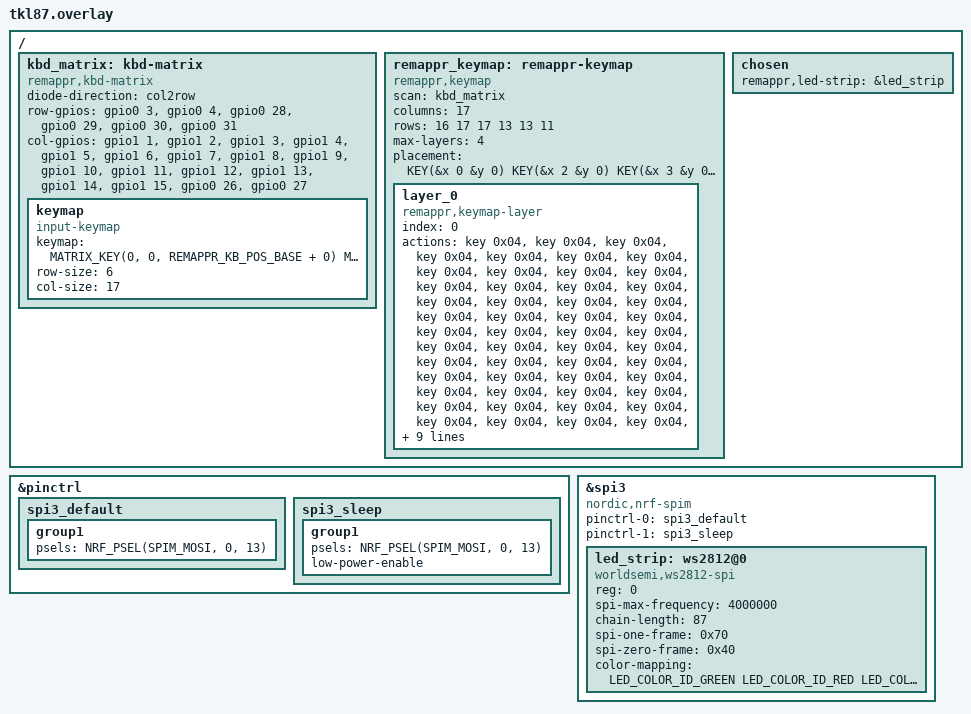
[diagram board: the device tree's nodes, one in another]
/*
 * TKL 87 — Remappr shield (generated by remappr).
 *
 * Drop this directory into a remappr-firmware checkout under
 * boards/shields/tkl87/ and build with -DSHIELD=tkl87. Verify the
 * row/col GPIO specs against your wiring — remappr derives the matrix
 * cells from physical key position, not the electrical matrix.
 *
 * SPDX-License-Identifier: Apache-2.0
 */

#include <zephyr/dt-bindings/input/input-event-codes.h>
#include <zephyr/dt-bindings/input/keymap.h>
#include <dt-bindings/remappr/keys.h>
#include <dt-bindings/remappr/layout.h>
#include <remappr/keymap-tokens.dtsi>
#include <remappr/behavior-tokens.dtsi>
#include <zephyr/dt-bindings/led/led.h>

/ {
	kbd_matrix: kbd-matrix {
		compatible = "remappr,kbd-matrix";
		diode-direction = "col2row";
		row-gpios =
			<&gpio0 3 (GPIO_ACTIVE_HIGH | GPIO_PULL_DOWN)>,
			<&gpio0 4 (GPIO_ACTIVE_HIGH | GPIO_PULL_DOWN)>,
			<&gpio0 28 (GPIO_ACTIVE_HIGH | GPIO_PULL_DOWN)>,
			<&gpio0 29 (GPIO_ACTIVE_HIGH | GPIO_PULL_DOWN)>,
			<&gpio0 30 (GPIO_ACTIVE_HIGH | GPIO_PULL_DOWN)>,
			<&gpio0 31 (GPIO_ACTIVE_HIGH | GPIO_PULL_DOWN)>;
		col-gpios =
			<&gpio1 1 GPIO_ACTIVE_HIGH>,
			<&gpio1 2 GPIO_ACTIVE_HIGH>,
			<&gpio1 3 GPIO_ACTIVE_HIGH>,
			<&gpio1 4 GPIO_ACTIVE_HIGH>,
			<&gpio1 5 GPIO_ACTIVE_HIGH>,
			<&gpio1 6 GPIO_ACTIVE_HIGH>,
			<&gpio1 7 GPIO_ACTIVE_HIGH>,
			<&gpio1 8 GPIO_ACTIVE_HIGH>,
			<&gpio1 9 GPIO_ACTIVE_HIGH>,
			<&gpio1 10 GPIO_ACTIVE_HIGH>,
			<&gpio1 11 GPIO_ACTIVE_HIGH>,
			<&gpio1 12 GPIO_ACTIVE_HIGH>,
			<&gpio1 13 GPIO_ACTIVE_HIGH>,
			<&gpio1 14 GPIO_ACTIVE_HIGH>,
			<&gpio1 15 GPIO_ACTIVE_HIGH>,
			<&gpio0 26 GPIO_ACTIVE_HIGH>,
			<&gpio0 27 GPIO_ACTIVE_HIGH>;

		keymap {
			compatible = "input-keymap";
			keymap = <
				MATRIX_KEY(0, 0, REMAPPR_KB_POS_BASE + 0) MATRIX_KEY(0, 1, REMAPPR_KB_POS_BASE + 1) MATRIX_KEY(0, 2, REMAPPR_KB_POS_BASE + 2) MATRIX_KEY(0, 3, REMAPPR_KB_POS_BASE + 3) MATRIX_KEY(0, 4, REMAPPR_KB_POS_BASE + 4) MATRIX_KEY(0, 5, REMAPPR_KB_POS_BASE + 5) MATRIX_KEY(0, 6, REMAPPR_KB_POS_BASE + 6) MATRIX_KEY(0, 7, REMAPPR_KB_POS_BASE + 7) MATRIX_KEY(0, 8, REMAPPR_KB_POS_BASE + 8) MATRIX_KEY(0, 9, REMAPPR_KB_POS_BASE + 9) MATRIX_KEY(0, 10, REMAPPR_KB_POS_BASE + 10) MATRIX_KEY(0, 11, REMAPPR_KB_POS_BASE + 11) MATRIX_KEY(0, 12, REMAPPR_KB_POS_BASE + 12) MATRIX_KEY(0, 13, REMAPPR_KB_POS_BASE + 13) MATRIX_KEY(0, 14, REMAPPR_KB_POS_BASE + 14) MATRIX_KEY(0, 15, REMAPPR_KB_POS_BASE + 15)
				MATRIX_KEY(1, 0, REMAPPR_KB_POS_BASE + 16) MATRIX_KEY(1, 1, REMAPPR_KB_POS_BASE + 17) MATRIX_KEY(1, 2, REMAPPR_KB_POS_BASE + 18) MATRIX_KEY(1, 3, REMAPPR_KB_POS_BASE + 19) MATRIX_KEY(1, 4, REMAPPR_KB_POS_BASE + 20) MATRIX_KEY(1, 5, REMAPPR_KB_POS_BASE + 21) MATRIX_KEY(1, 6, REMAPPR_KB_POS_BASE + 22) MATRIX_KEY(1, 7, REMAPPR_KB_POS_BASE + 23) MATRIX_KEY(1, 8, REMAPPR_KB_POS_BASE + 24) MATRIX_KEY(1, 9, REMAPPR_KB_POS_BASE + 25) MATRIX_KEY(1, 10, REMAPPR_KB_POS_BASE + 26) MATRIX_KEY(1, 11, REMAPPR_KB_POS_BASE + 27) MATRIX_KEY(1, 12, REMAPPR_KB_POS_BASE + 28) MATRIX_KEY(1, 13, REMAPPR_KB_POS_BASE + 29) MATRIX_KEY(1, 14, REMAPPR_KB_POS_BASE + 30) MATRIX_KEY(1, 15, REMAPPR_KB_POS_BASE + 31) MATRIX_KEY(1, 16, REMAPPR_KB_POS_BASE + 32)
				MATRIX_KEY(2, 0, REMAPPR_KB_POS_BASE + 33) MATRIX_KEY(2, 1, REMAPPR_KB_POS_BASE + 34) MATRIX_KEY(2, 2, REMAPPR_KB_POS_BASE + 35) MATRIX_KEY(2, 3, REMAPPR_KB_POS_BASE + 36) MATRIX_KEY(2, 4, REMAPPR_KB_POS_BASE + 37) MATRIX_KEY(2, 5, REMAPPR_KB_POS_BASE + 38) MATRIX_KEY(2, 6, REMAPPR_KB_POS_BASE + 39) MATRIX_KEY(2, 7, REMAPPR_KB_POS_BASE + 40) MATRIX_KEY(2, 8, REMAPPR_KB_POS_BASE + 41) MATRIX_KEY(2, 9, REMAPPR_KB_POS_BASE + 42) MATRIX_KEY(2, 10, REMAPPR_KB_POS_BASE + 43) MATRIX_KEY(2, 11, REMAPPR_KB_POS_BASE + 44) MATRIX_KEY(2, 12, REMAPPR_KB_POS_BASE + 45) MATRIX_KEY(2, 13, REMAPPR_KB_POS_BASE + 46) MATRIX_KEY(2, 14, REMAPPR_KB_POS_BASE + 47) MATRIX_KEY(2, 15, REMAPPR_KB_POS_BASE + 48) MATRIX_KEY(2, 16, REMAPPR_KB_POS_BASE + 49)
				MATRIX_KEY(3, 0, REMAPPR_KB_POS_BASE + 50) MATRIX_KEY(3, 1, REMAPPR_KB_POS_BASE + 51) MATRIX_KEY(3, 2, REMAPPR_KB_POS_BASE + 52) MATRIX_KEY(3, 3, REMAPPR_KB_POS_BASE + 53) MATRIX_KEY(3, 4, REMAPPR_KB_POS_BASE + 54) MATRIX_KEY(3, 5, REMAPPR_KB_POS_BASE + 55) MATRIX_KEY(3, 6, REMAPPR_KB_POS_BASE + 56) MATRIX_KEY(3, 7, REMAPPR_KB_POS_BASE + 57) MATRIX_KEY(3, 8, REMAPPR_KB_POS_BASE + 58) MATRIX_KEY(3, 9, REMAPPR_KB_POS_BASE + 59) MATRIX_KEY(3, 10, REMAPPR_KB_POS_BASE + 60) MATRIX_KEY(3, 11, REMAPPR_KB_POS_BASE + 61) MATRIX_KEY(3, 12, REMAPPR_KB_POS_BASE + 62)
				MATRIX_KEY(4, 0, REMAPPR_KB_POS_BASE + 63) MATRIX_KEY(4, 1, REMAPPR_KB_POS_BASE + 64) MATRIX_KEY(4, 2, REMAPPR_KB_POS_BASE + 65) MATRIX_KEY(4, 3, REMAPPR_KB_POS_BASE + 66) MATRIX_KEY(4, 4, REMAPPR_KB_POS_BASE + 67) MATRIX_KEY(4, 5, REMAPPR_KB_POS_BASE + 68) MATRIX_KEY(4, 6, REMAPPR_KB_POS_BASE + 69) MATRIX_KEY(4, 7, REMAPPR_KB_POS_BASE + 70) MATRIX_KEY(4, 8, REMAPPR_KB_POS_BASE + 71) MATRIX_KEY(4, 9, REMAPPR_KB_POS_BASE + 72) MATRIX_KEY(4, 10, REMAPPR_KB_POS_BASE + 73) MATRIX_KEY(4, 11, REMAPPR_KB_POS_BASE + 74) MATRIX_KEY(4, 12, REMAPPR_KB_POS_BASE + 75)
				MATRIX_KEY(5, 0, REMAPPR_KB_POS_BASE + 76) MATRIX_KEY(5, 1, REMAPPR_KB_POS_BASE + 77) MATRIX_KEY(5, 2, REMAPPR_KB_POS_BASE + 78) MATRIX_KEY(5, 3, REMAPPR_KB_POS_BASE + 79) MATRIX_KEY(5, 4, REMAPPR_KB_POS_BASE + 80) MATRIX_KEY(5, 5, REMAPPR_KB_POS_BASE + 81) MATRIX_KEY(5, 6, REMAPPR_KB_POS_BASE + 82) MATRIX_KEY(5, 7, REMAPPR_KB_POS_BASE + 83) MATRIX_KEY(5, 8, REMAPPR_KB_POS_BASE + 84) MATRIX_KEY(5, 9, REMAPPR_KB_POS_BASE + 85) MATRIX_KEY(5, 10, REMAPPR_KB_POS_BASE + 86)
			>;
			row-size = <6>;
			col-size = <17>;
		};
	};

	remappr_keymap: remappr-keymap {
		compatible = "remappr,keymap";
		scan = <&kbd_matrix>;
		columns = <17>;
		rows = <16 17 17 13 13 11>;
		max-layers = <4>;
		placement = <
				KEY(&x 0 &y 0) KEY(&x 2 &y 0) KEY(&x 3 &y 0) KEY(&x 4 &y 0) KEY(&x 5 &y 0) KEY(&x 7 &y 0) KEY(&x 8 &y 0) KEY(&x 9 &y 0) KEY(&x 10 &y 0) KEY(&x 11 &y 0) KEY(&x 12 &y 0) KEY(&x 13 &y 0) KEY(&x 14 &y 0) KEY(&x 15 &y 0) KEY(&x 16 &y 0) KEY(&x 17 &y 0)
				KEY(&x 0 &y 2) KEY(&x 1 &y 2) KEY(&x 2 &y 2) KEY(&x 3 &y 2) KEY(&x 4 &y 2) KEY(&x 5 &y 2) KEY(&x 6 &y 2) KEY(&x 7 &y 2) KEY(&x 8 &y 2) KEY(&x 9 &y 2) KEY(&x 10 &y 2) KEY(&x 11 &y 2) KEY(&x 12 &y 2) KEY(&x 13 &y 2 &w 2) KEY(&x 15 &y 2) KEY(&x 16 &y 2) KEY(&x 17 &y 2)
				KEY(&x 0 &y 3 &w 2) KEY(&x 2 &y 3) KEY(&x 3 &y 3) KEY(&x 4 &y 3) KEY(&x 5 &y 3) KEY(&x 6 &y 3) KEY(&x 7 &y 3) KEY(&x 8 &y 3) KEY(&x 9 &y 3) KEY(&x 10 &y 3) KEY(&x 11 &y 3) KEY(&x 12 &y 3) KEY(&x 13 &y 3) KEY(&x 14 &y 3 &w 2) KEY(&x 15 &y 3) KEY(&x 16 &y 3) KEY(&x 17 &y 3)
				KEY(&x 0 &y 4 &w 2) KEY(&x 2 &y 4) KEY(&x 3 &y 4) KEY(&x 4 &y 4) KEY(&x 5 &y 4) KEY(&x 6 &y 4) KEY(&x 7 &y 4) KEY(&x 8 &y 4) KEY(&x 9 &y 4) KEY(&x 10 &y 4) KEY(&x 11 &y 4) KEY(&x 12 &y 4) KEY(&x 13 &y 4 &w 2)
				KEY(&x 0 &y 5 &w 2) KEY(&x 2 &y 5) KEY(&x 3 &y 5) KEY(&x 4 &y 5) KEY(&x 5 &y 5) KEY(&x 6 &y 5) KEY(&x 7 &y 5) KEY(&x 8 &y 5) KEY(&x 9 &y 5) KEY(&x 10 &y 5) KEY(&x 11 &y 5) KEY(&x 12 &y 5 &w 3) KEY(&x 16 &y 5)
				KEY(&x 0 &y 6) KEY(&x 1 &y 6) KEY(&x 3 &y 6) KEY(&x 4 &y 6 &w 6) KEY(&x 10 &y 6) KEY(&x 11 &y 6) KEY(&x 13 &y 6) KEY(&x 14 &y 6) KEY(&x 15 &y 6) KEY(&x 16 &y 6) KEY(&x 17 &y 6)
		>;
		layer_0 {
			compatible = "remappr,keymap-layer";
			index = <0>;
			actions = <
				&key 0x04 &key 0x04 &key 0x04 &key 0x04 &key 0x04 &key 0x04 &key 0x04 &key 0x04 &key 0x04 &key 0x04 &key 0x04 &key 0x04 &key 0x04 &key 0x04 &key 0x04 &key 0x04
				&key 0x04 &key 0x04 &key 0x04 &key 0x04 &key 0x04 &key 0x04 &key 0x04 &key 0x04 &key 0x04 &key 0x04 &key 0x04 &key 0x04 &key 0x04 &key 0x04 &key 0x04 &key 0x04 &key 0x04
				&key 0x04 &key 0x04 &key 0x04 &key 0x04 &key 0x04 &key 0x04 &key 0x04 &key 0x04 &key 0x04 &key 0x04 &key 0x04 &key 0x04 &key 0x04 &key 0x04 &key 0x04 &key 0x04 &key 0x04
				&key 0x04 &key 0x04 &key 0x04 &key 0x04 &key 0x04 &key 0x04 &key 0x04 &key 0x04 &key 0x04 &key 0x04 &key 0x04 &key 0x04 &key 0x04
				&key 0x04 &key 0x04 &key 0x04 &key 0x04 &key 0x04 &key 0x04 &key 0x04 &key 0x04 &key 0x04 &key 0x04 &key 0x04 &key 0x04 &key 0x04
				&key 0x04 &key 0x04 &key 0x04 &key 0x04 &key 0x04 &key 0x04 &key 0x04 &key 0x04 &key 0x04 &key 0x04 &key 0x04
			>;
		};
	};
};

&pinctrl {
	spi3_default: spi3_default {
		group1 {
			psels = <NRF_PSEL(SPIM_MOSI, 0, 13)>;
		};
	};
	spi3_sleep: spi3_sleep {
		group1 {
			psels = <NRF_PSEL(SPIM_MOSI, 0, 13)>;
			low-power-enable;
		};
	};
};

&spi3 {
	compatible = "nordic,nrf-spim";
	status = "okay";
	pinctrl-0 = <&spi3_default>;
	pinctrl-1 = <&spi3_sleep>;
	pinctrl-names = "default", "sleep";

	led_strip: ws2812@0 {
		compatible = "worldsemi,ws2812-spi";
		reg = <0>;
		spi-max-frequency = <4000000>;
		chain-length = <87>;
		/* One low lead-in bit, then the pulse: 4000000 Hz SPI clock. */
		spi-one-frame = <0x70>;
		spi-zero-frame = <0x40>;
		color-mapping = <LED_COLOR_ID_GREEN LED_COLOR_ID_RED LED_COLOR_ID_BLUE>;
	};
};

/ {
	chosen {
		/* Runtime RGB service renders the per-key map / effects here. */
		remappr,led-strip = &led_strip;
	};
};
